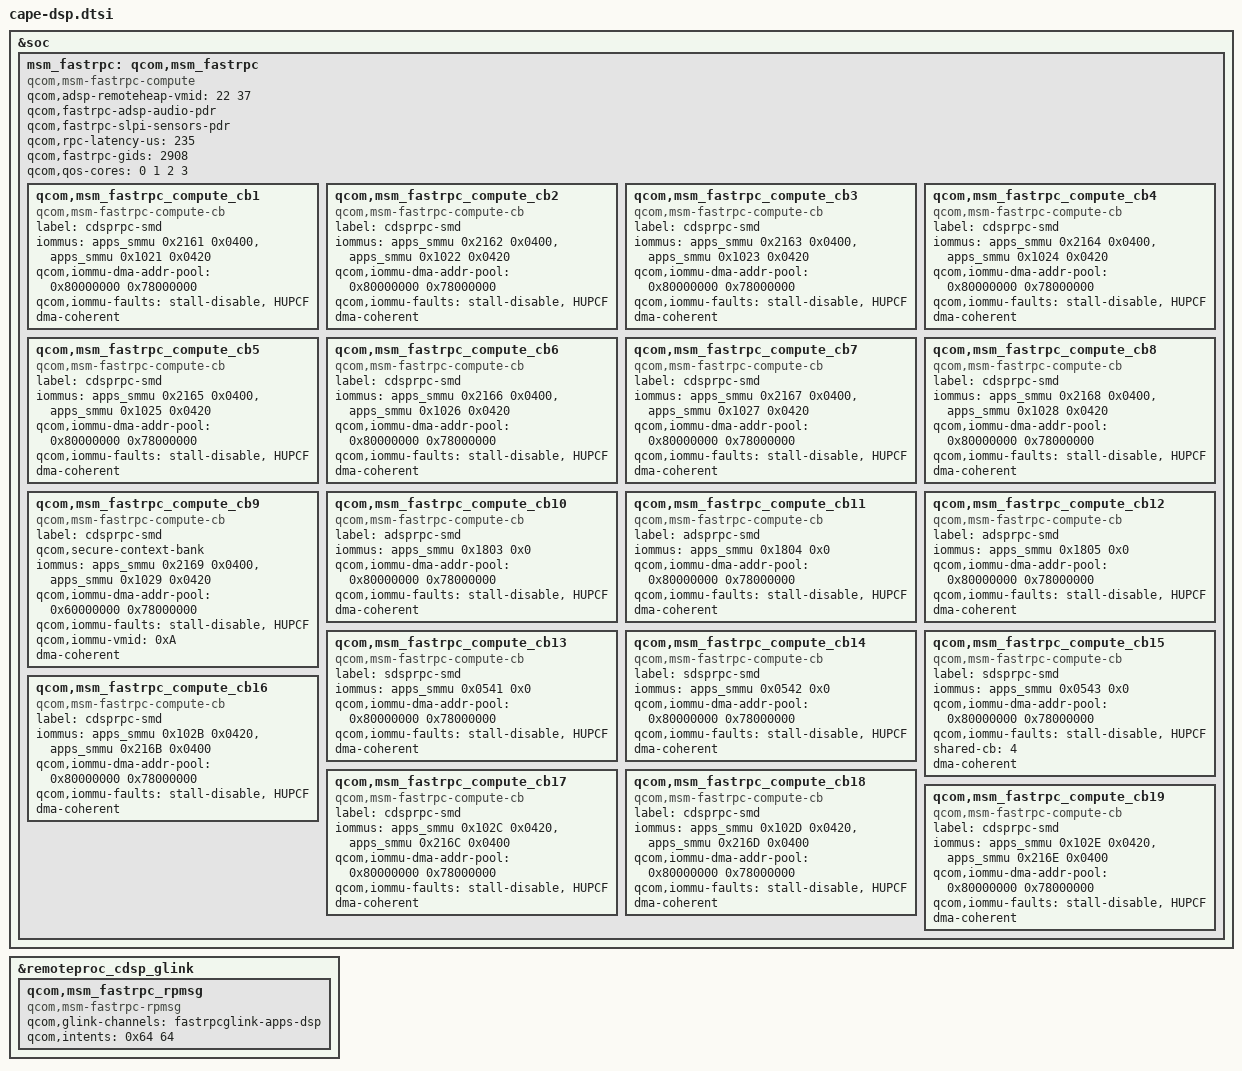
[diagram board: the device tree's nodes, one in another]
// SPDX-License-Identifier: BSD-3-Clause
/*
 * Copyright (c) 2024 Qualcomm Innovation Center, Inc. All rights reserved.
 */
&soc {
	msm_fastrpc: qcom,msm_fastrpc {
		compatible = "qcom,msm-fastrpc-compute";
		qcom,adsp-remoteheap-vmid = <22 37>;
		qcom,fastrpc-adsp-audio-pdr;
		qcom,fastrpc-slpi-sensors-pdr;
		qcom,rpc-latency-us = <235>;
		qcom,fastrpc-gids = <2908>;
		qcom,qos-cores = <0 1 2 3>;

		qcom,msm_fastrpc_compute_cb1 {
			compatible = "qcom,msm-fastrpc-compute-cb";
			label = "cdsprpc-smd";
			iommus = <&apps_smmu 0x2161 0x0400>,
					 <&apps_smmu 0x1021 0x0420>;
			qcom,iommu-dma-addr-pool = <0x80000000 0x78000000>;
			qcom,iommu-faults = "stall-disable", "HUPCF";
			dma-coherent;
		};

		qcom,msm_fastrpc_compute_cb2 {
			compatible = "qcom,msm-fastrpc-compute-cb";
			label = "cdsprpc-smd";
			iommus = <&apps_smmu 0x2162 0x0400>,
					 <&apps_smmu 0x1022 0x0420>;
			qcom,iommu-dma-addr-pool = <0x80000000 0x78000000>;
			qcom,iommu-faults = "stall-disable", "HUPCF";
			dma-coherent;
		};

		qcom,msm_fastrpc_compute_cb3 {
			compatible = "qcom,msm-fastrpc-compute-cb";
			label = "cdsprpc-smd";
			iommus = <&apps_smmu 0x2163 0x0400>,
					 <&apps_smmu 0x1023 0x0420>;
			qcom,iommu-dma-addr-pool = <0x80000000 0x78000000>;
			qcom,iommu-faults = "stall-disable", "HUPCF";
			dma-coherent;
		};

		qcom,msm_fastrpc_compute_cb4 {
			compatible = "qcom,msm-fastrpc-compute-cb";
			label = "cdsprpc-smd";
			iommus = <&apps_smmu 0x2164 0x0400>,
					 <&apps_smmu 0x1024 0x0420>;
			qcom,iommu-dma-addr-pool = <0x80000000 0x78000000>;
			qcom,iommu-faults = "stall-disable", "HUPCF";
			dma-coherent;
		};

		qcom,msm_fastrpc_compute_cb5 {
			compatible = "qcom,msm-fastrpc-compute-cb";
			label = "cdsprpc-smd";
			iommus = <&apps_smmu 0x2165 0x0400>,
					 <&apps_smmu 0x1025 0x0420>;
			qcom,iommu-dma-addr-pool = <0x80000000 0x78000000>;
			qcom,iommu-faults = "stall-disable", "HUPCF";
			dma-coherent;
		};

		qcom,msm_fastrpc_compute_cb6 {
			compatible = "qcom,msm-fastrpc-compute-cb";
			label = "cdsprpc-smd";
			iommus = <&apps_smmu 0x2166 0x0400>,
					 <&apps_smmu 0x1026 0x0420>;
			qcom,iommu-dma-addr-pool = <0x80000000 0x78000000>;
			qcom,iommu-faults = "stall-disable", "HUPCF";
			dma-coherent;
		};

		qcom,msm_fastrpc_compute_cb7 {
			compatible = "qcom,msm-fastrpc-compute-cb";
			label = "cdsprpc-smd";
			iommus = <&apps_smmu 0x2167 0x0400>,
					 <&apps_smmu 0x1027 0x0420>;
			qcom,iommu-dma-addr-pool = <0x80000000 0x78000000>;
			qcom,iommu-faults = "stall-disable", "HUPCF";
			dma-coherent;
		};

		qcom,msm_fastrpc_compute_cb8 {
			compatible = "qcom,msm-fastrpc-compute-cb";
			label = "cdsprpc-smd";
			iommus = <&apps_smmu 0x2168 0x0400>,
					 <&apps_smmu 0x1028 0x0420>;
			qcom,iommu-dma-addr-pool = <0x80000000 0x78000000>;
			qcom,iommu-faults = "stall-disable", "HUPCF";
			dma-coherent;
		};

		qcom,msm_fastrpc_compute_cb9 {
			compatible = "qcom,msm-fastrpc-compute-cb";
			label = "cdsprpc-smd";
			qcom,secure-context-bank;
			iommus = <&apps_smmu 0x2169 0x0400>,
					 <&apps_smmu 0x1029 0x0420>;
			qcom,iommu-dma-addr-pool = <0x60000000 0x78000000>;
			qcom,iommu-faults = "stall-disable", "HUPCF";
			qcom,iommu-vmid = <0xA>;	/* VMID_CP_PIXEL */
			dma-coherent;
		};

		qcom,msm_fastrpc_compute_cb10 {
			compatible = "qcom,msm-fastrpc-compute-cb";
			label = "adsprpc-smd";
			iommus = <&apps_smmu 0x1803 0x0>;
			qcom,iommu-dma-addr-pool = <0x80000000 0x78000000>;
			qcom,iommu-faults = "stall-disable", "HUPCF";
			dma-coherent;
		};

		qcom,msm_fastrpc_compute_cb11 {
			compatible = "qcom,msm-fastrpc-compute-cb";
			label = "adsprpc-smd";
			iommus = <&apps_smmu 0x1804 0x0>;
			qcom,iommu-dma-addr-pool = <0x80000000 0x78000000>;
			qcom,iommu-faults = "stall-disable", "HUPCF";
			dma-coherent;
		};

		qcom,msm_fastrpc_compute_cb12 {
			compatible = "qcom,msm-fastrpc-compute-cb";
			label = "adsprpc-smd";
			iommus = <&apps_smmu 0x1805 0x0>;
			qcom,iommu-dma-addr-pool = <0x80000000 0x78000000>;
			qcom,iommu-faults = "stall-disable", "HUPCF";
			dma-coherent;
		};

		qcom,msm_fastrpc_compute_cb13 {
			compatible = "qcom,msm-fastrpc-compute-cb";
			label = "sdsprpc-smd";
			iommus = <&apps_smmu 0x0541 0x0>;
			qcom,iommu-dma-addr-pool = <0x80000000 0x78000000>;
			qcom,iommu-faults = "stall-disable", "HUPCF";
			dma-coherent;
		};

		qcom,msm_fastrpc_compute_cb14 {
			compatible = "qcom,msm-fastrpc-compute-cb";
			label = "sdsprpc-smd";
			iommus = <&apps_smmu 0x0542 0x0>;
			qcom,iommu-dma-addr-pool = <0x80000000 0x78000000>;
			qcom,iommu-faults = "stall-disable", "HUPCF";
			dma-coherent;
		};

		qcom,msm_fastrpc_compute_cb15 {
			compatible = "qcom,msm-fastrpc-compute-cb";
			label = "sdsprpc-smd";
			iommus = <&apps_smmu 0x0543 0x0>;
			qcom,iommu-dma-addr-pool = <0x80000000 0x78000000>;
			qcom,iommu-faults = "stall-disable", "HUPCF";
			shared-cb = <4>;
			dma-coherent;
		};

		qcom,msm_fastrpc_compute_cb16 {
			compatible = "qcom,msm-fastrpc-compute-cb";
			label = "cdsprpc-smd";
			iommus = <&apps_smmu 0x102B 0x0420>,
					 <&apps_smmu 0x216B 0x0400>;
			qcom,iommu-dma-addr-pool = <0x80000000 0x78000000>;
			qcom,iommu-faults = "stall-disable", "HUPCF";
			dma-coherent;
		};

		qcom,msm_fastrpc_compute_cb17 {
			compatible = "qcom,msm-fastrpc-compute-cb";
			label = "cdsprpc-smd";
			iommus = <&apps_smmu 0x102C 0x0420>,
					 <&apps_smmu 0x216C 0x0400>;
			qcom,iommu-dma-addr-pool = <0x80000000 0x78000000>;
			qcom,iommu-faults = "stall-disable", "HUPCF";
			dma-coherent;
		};

		qcom,msm_fastrpc_compute_cb18 {
			compatible = "qcom,msm-fastrpc-compute-cb";
			label = "cdsprpc-smd";
			iommus = <&apps_smmu 0x102D 0x0420>,
					 <&apps_smmu 0x216D 0x0400>;
			qcom,iommu-dma-addr-pool = <0x80000000 0x78000000>;
			qcom,iommu-faults = "stall-disable", "HUPCF";
			dma-coherent;
		};

		qcom,msm_fastrpc_compute_cb19 {
			compatible = "qcom,msm-fastrpc-compute-cb";
			label = "cdsprpc-smd";
			iommus = <&apps_smmu 0x102E 0x0420>,
					 <&apps_smmu 0x216E 0x0400>;
			qcom,iommu-dma-addr-pool = <0x80000000 0x78000000>;
			qcom,iommu-faults = "stall-disable", "HUPCF";
			dma-coherent;
		};
	};
};

&remoteproc_cdsp_glink {
	qcom,msm_fastrpc_rpmsg {
		compatible = "qcom,msm-fastrpc-rpmsg";
		qcom,glink-channels = "fastrpcglink-apps-dsp";
		qcom,intents = <0x64 64>;
	};
};
